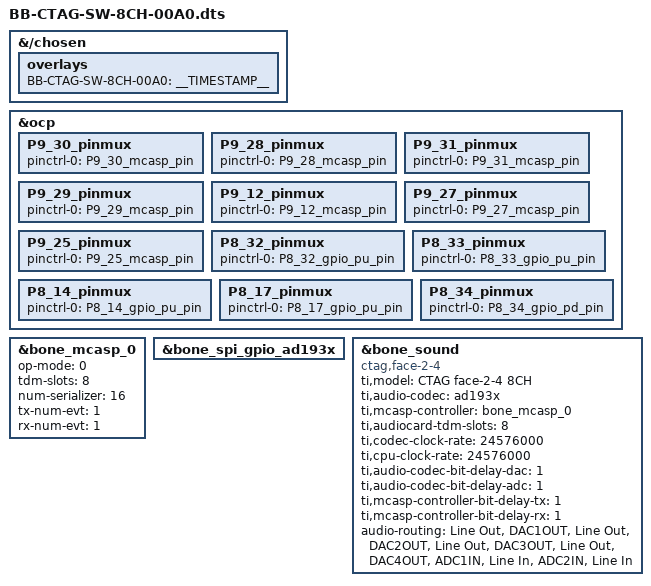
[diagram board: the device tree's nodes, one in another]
/*
 * Copyright (C) 2020 Deepak Khatri <deepaklorkhatri7@gmail.com>
 * See Cape Interface Spec page for more info on Bone Buses
 * https://elinux.org/Beagleboard:BeagleBone_cape_interface_spec
 * Device Tree Overlay for CTAG face2|4 multichannel soundcard - 8 audio channels
 *
 * Based on the BB-CTAG-SW-8CH-00A0.dts for kernel <4.14 written by
 * Copyright (C) Henrik Langer <henni19790@googlemail.com>
 *
 * This program is free software; you can redistribute it and/or modify
 * it under the terms of the GNU General Public License version 3 as
 * published by the Free Software Foundation.
 */
/dts-v1/;
/plugin/;

/*
 * Helper to show loaded overlays under: /proc/device-tree/chosen/overlays/
 */
&{/chosen} {
	overlays {
		BB-CTAG-SW-8CH-00A0 = __TIMESTAMP__;
	};
};

/*
 * Update the default pinmux of the pins.
 * See these files for the phandles (&P9_* & &P8_*)
 * BeagleBoard-DeviceTrees/v4.19.x-ti-overlays/src/arm/am335x-bone-common-univ.dtsi
 * BeagleBoard-DeviceTrees/v4.19.x-ti-overlays/src/arm/am572x-bone-common-univ.dtsi
 */
&ocp {
	P9_30_pinmux { pinctrl-0 = <&P9_30_mcasp_pin>; }; /* mcasp axr - audio in */
	P9_28_pinmux { pinctrl-0 = <&P9_28_mcasp_pin>; }; /* mcasp axr - audio out */
	P9_31_pinmux { pinctrl-0 = <&P9_31_mcasp_pin>; }; /* mcasp ahclkx - transmit bitclock */
	P9_29_pinmux { pinctrl-0 = <&P9_29_mcasp_pin>; }; /* mcasp fsx - transmit frameclock */
	P9_12_pinmux { pinctrl-0 = <&P9_12_mcasp_pin>; }; /* mcasp aclkr - receive bitclock */
	P9_27_pinmux { pinctrl-0 = <&P9_27_mcasp_pin>; }; /* mcasp fsr - receive frameclock */
	P9_25_pinmux { pinctrl-0 = <&P9_25_mcasp_pin>; }; /* mcasp ahclkx - masterclock */
	P8_32_pinmux { pinctrl-0 = <&P8_32_gpio_pu_pin>; }; /* spi_sclk */
	P8_33_pinmux { pinctrl-0 = <&P8_33_gpio_pu_pin>; }; /* spi_mosi */
	P8_14_pinmux { pinctrl-0 = <&P8_14_gpio_pu_pin>; }; /* spi_miso */
	P8_17_pinmux { pinctrl-0 = <&P8_17_gpio_pu_pin>; }; /* spi_cs0 */
	P8_34_pinmux { pinctrl-0 = <&P8_34_gpio_pd_pin>; }; /* spi_reset-gpio */
};

/*
 * See these files for the phandles (&bone_*) and other bone bus nodes
 * BeagleBoard-DeviceTrees/v4.19.x-ti-overlays/src/arm/bbai-bone-buses.dtsi
 * BeagleBoard-DeviceTrees/v4.19.x-ti-overlays/src/arm/bbb-bone-buses.dtsi
 */
&bone_mcasp_0 {
	status = "okay";
	op-mode = <0>;	/* MCASP_IIS_MODE */
	tdm-slots = <8>;
	num-serializer = <16>;
	tx-num-evt = <1>;
	rx-num-evt = <1>;
};

&bone_spi_gpio_ad193x {
	status = "okay";
};

&bone_sound {
	compatible = "ctag,face-2-4";
	ti,model = "CTAG face-2-4 8CH";
	ti,audio-codec = <&ad193x>;
	ti,mcasp-controller = <&bone_mcasp_0>;
	ti,audiocard-tdm-slots = <8>;
	ti,codec-clock-rate = <24576000>;
	ti,cpu-clock-rate = <24576000>;
	status = "okay";

	ti,audio-codec-bit-delay-dac = <1>; //currently only supports 1 or 0 bit delay
	ti,audio-codec-bit-delay-adc = <1>;
	ti,mcasp-controller-bit-delay-tx = <1>;
	ti,mcasp-controller-bit-delay-rx = <1>;

	audio-routing =
		"Line Out",             "DAC1OUT",
		"Line Out",             "DAC2OUT",
		"Line Out",             "DAC3OUT",
		"Line Out",             "DAC4OUT",
		"ADC1IN",               "Line In",
		"ADC2IN",               "Line In";
};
